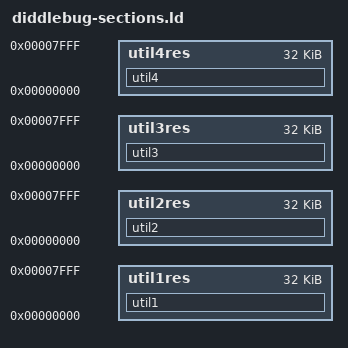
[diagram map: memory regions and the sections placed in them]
/* DO NOT EDIT!
   This file was automatically generated by m68k-palmos-multigen v2.3
   from diddlebug.def  */

MEMORY
{
	util1res : ORIGIN = 0x0, LENGTH = 32768
	util2res : ORIGIN = 0x0, LENGTH = 32768
	util3res : ORIGIN = 0x0, LENGTH = 32768
	util4res : ORIGIN = 0x0, LENGTH = 32768
}

SECTIONS
{
	util1 : { *(util1) } > util1res
	util2 : { *(util2) } > util2res
	util3 : { *(util3) } > util3res
	util4 : { *(util4) } > util4res
}
